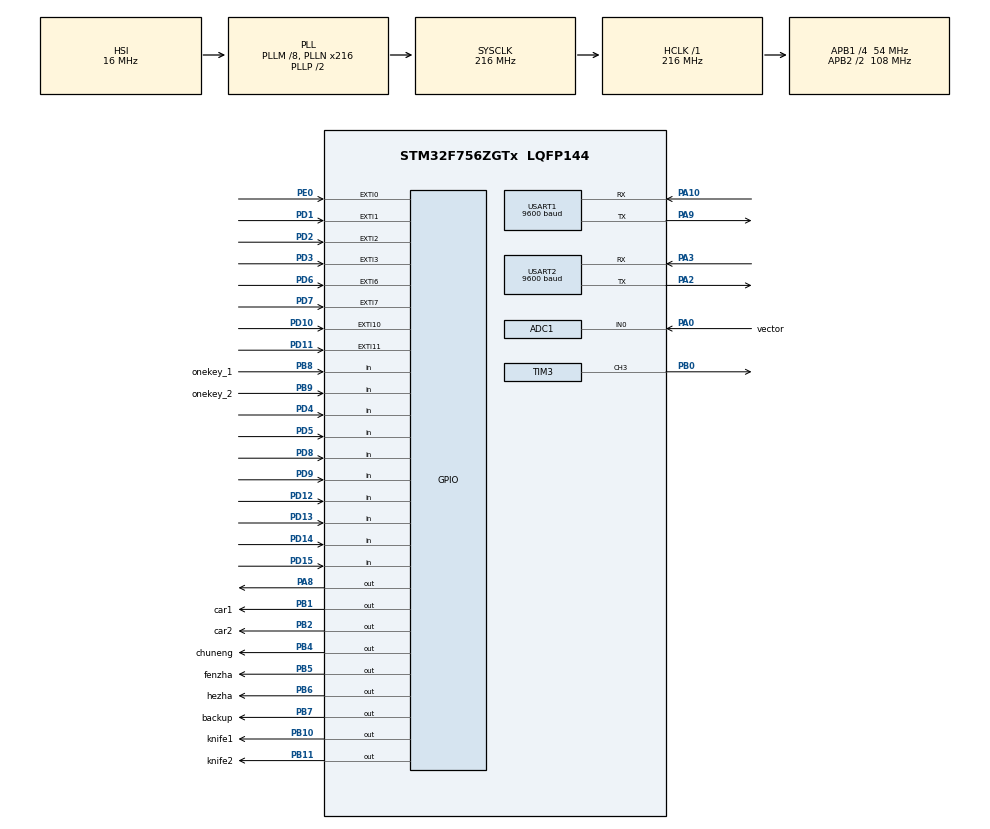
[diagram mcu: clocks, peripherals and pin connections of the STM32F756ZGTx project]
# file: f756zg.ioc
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ADC1.Channel-2\#ChannelRegularConversion=ADC_CHANNEL_0
ADC1.ClockPrescaler=ADC_CLOCK_SYNC_PCLK_DIV8
ADC1.ContinuousConvMode=ENABLE
ADC1.DMAContinuousRequests=ENABLE
ADC1.InjNumberOfConversion=0
ADC1.NbrOfConversionFlag=1
ADC1.Rank-2\#ChannelRegularConversion=1
ADC1.SamplingTime-2\#ChannelRegularConversion=ADC_SAMPLETIME_480CYCLES
ADC1.ScanConvMode=ADC_SCAN_ENABLE
ADC1.master=1
Dma.ADC1.0.Direction=DMA_PERIPH_TO_MEMORY
Dma.ADC1.0.FIFOMode=DMA_FIFOMODE_DISABLE
Dma.ADC1.0.Instance=DMA2_Stream0
Dma.ADC1.0.MemDataAlignment=DMA_MDATAALIGN_WORD
Dma.ADC1.0.MemInc=DMA_MINC_ENABLE
Dma.ADC1.0.Mode=DMA_CIRCULAR
Dma.ADC1.0.PeriphDataAlignment=DMA_PDATAALIGN_WORD
Dma.ADC1.0.PeriphInc=DMA_PINC_DISABLE
Dma.ADC1.0.Priority=DMA_PRIORITY_LOW
Dma.Request0=ADC1
Mcu.Family=STM32F7
Mcu.Name=STM32F756ZGTx
Mcu.Package=LQFP144
NVIC.DMA2_Stream0_IRQn=true\:0\:0\:false\:false\:true\:false\:true
NVIC.EXTI0_IRQn=true\:2\:0\:true\:false\:true\:true\:true
NVIC.EXTI15_10_IRQn=true\:2\:0\:true\:false\:true\:true\:true
NVIC.EXTI1_IRQn=true\:2\:0\:true\:false\:true\:true\:true
NVIC.EXTI2_IRQn=true\:2\:0\:true\:false\:true\:true\:true
NVIC.EXTI3_IRQn=true\:2\:0\:true\:false\:true\:true\:true
NVIC.EXTI9_5_IRQn=true\:2\:0\:true\:false\:true\:true\:true
NVIC.PriorityGroup=NVIC_PRIORITYGROUP_4
NVIC.TIM3_IRQn=true\:1\:0\:true\:false\:true\:true\:true
NVIC.TIM6_DAC_IRQn=true\:5\:0\:true\:true\:true\:1\:true\:true
PA0/WKUP.GPIO_Label=vector
PA0/WKUP.Signal=SharedAnalog_PA0
PA10.Mode=Asynchronous
PA10.Signal=USART1_RX
PA13.Mode=Serial_Wire
PA13.Signal=SYS_JTMS-SWDIO
PA14.Mode=Serial_Wire
PA14.Signal=SYS_JTCK-SWCLK
PA2.Mode=Asynchronous
PA2.Signal=USART2_TX
PA3.Mode=Asynchronous
PA3.Signal=USART2_RX
PA8.Signal=GPIO_Output
PA9.Mode=Asynchronous
PA9.Signal=USART1_TX
PB0.Signal=S_TIM3_CH3
PB1.GPIO_Label=car1
PB1.Signal=GPIO_Output
PB10.GPIO_Label=knife1
PB10.Signal=GPIO_Output
PB11.GPIO_Label=knife2
PB11.Signal=GPIO_Output
PB2.GPIO_Label=car2
PB2.Signal=GPIO_Output
PB4.GPIO_Label=chuneng
PB4.GPIO_ModeDefaultOutputPP=GPIO_MODE_OUTPUT_PP
PB4.GPIO_PuPd=GPIO_NOPULL
PB4.GPIO_Speed=GPIO_SPEED_FREQ_LOW
PB4.PinState=GPIO_PIN_RESET
PB4.Signal=GPIO_Output
PB5.GPIO_Label=fenzha
PB5.Signal=GPIO_Output
PB6.GPIO_Label=hezha
PB6.Signal=GPIO_Output
PB7.GPIO_Label=backup
PB7.Signal=GPIO_Output
PB8.GPIO_Label=onekey_1
PB8.GPIO_PuPd=GPIO_PULLDOWN
PB8.Signal=GPIO_Input
PB9.GPIO_Label=onekey_2
PB9.GPIO_PuPd=GPIO_PULLDOWN
PB9.Signal=GPIO_Input
PD1.GPIO_ModeDefaultEXTI=GPIO_MODE_IT_RISING
PD1.GPIO_PuPd=GPIO_PULLUP
PD1.Signal=GPXTI1
PD10.GPIO_ModeDefaultEXTI=GPIO_MODE_IT_RISING
PD10.GPIO_PuPd=GPIO_PULLUP
PD10.Signal=GPXTI10
PD11.GPIO_ModeDefaultEXTI=GPIO_MODE_IT_RISING
PD11.GPIO_PuPd=GPIO_PULLUP
PD11.Signal=GPXTI11
PD12.GPIO_PuPd=GPIO_PULLDOWN
PD12.Signal=GPIO_Input
PD13.GPIO_PuPd=GPIO_PULLDOWN
PD13.Signal=GPIO_Input
PD14.GPIO_PuPd=GPIO_PULLDOWN
PD14.Signal=GPIO_Input
PD15.GPIO_PuPd=GPIO_PULLDOWN
PD15.Signal=GPIO_Input
PD2.GPIO_ModeDefaultEXTI=GPIO_MODE_IT_RISING
PD2.GPIO_PuPd=GPIO_PULLUP
PD2.Signal=GPXTI2
PD3.GPIO_ModeDefaultEXTI=GPIO_MODE_IT_RISING
PD3.GPIO_PuPd=GPIO_PULLUP
PD3.Signal=GPXTI3
PD4.GPIO_PuPd=GPIO_PULLDOWN
PD4.Signal=GPIO_Input
PD5.GPIO_PuPd=GPIO_PULLDOWN
PD5.Signal=GPIO_Input
PD6.GPIO_ModeDefaultEXTI=GPIO_MODE_IT_RISING
PD6.GPIO_PuPd=GPIO_PULLUP
PD6.Signal=GPXTI6
PD7.GPIO_ModeDefaultEXTI=GPIO_MODE_IT_RISING
PD7.GPIO_PuPd=GPIO_PULLUP
PD7.Signal=GPXTI7
PD8.GPIO_PuPd=GPIO_PULLDOWN
PD8.Signal=GPIO_Input
PD9.GPIO_PuPd=GPIO_PULLDOWN
PD9.Signal=GPIO_Input
PE0.GPIO_ModeDefaultEXTI=GPIO_MODE_IT_RISING
PE0.GPIO_PuPd=GPIO_PULLUP
PE0.Signal=GPXTI0
PH0/OSC_IN.Mode=HSE-External-Oscillator
PH0/OSC_IN.Signal=RCC_OSC_IN
PH1/OSC_OUT.Mode=HSE-External-Oscillator
PH1/OSC_OUT.Signal=RCC_OSC_OUT
ProjectManager.HeapSize=0x200
ProjectManager.StackSize=0x400
ProjectManager.TargetToolchain=STM32CubeIDE
RCC.AHBFreq_Value=216000000
RCC.APB1CLKDivider=RCC_HCLK_DIV4
RCC.APB1Freq_Value=54000000
RCC.APB1TimFreq_Value=108000000
RCC.APB2CLKDivider=RCC_HCLK_DIV2
RCC.APB2Freq_Value=108000000
RCC.APB2TimFreq_Value=216000000
RCC.CortexFreq_Value=216000000
RCC.HCLKFreq_Value=216000000
RCC.HSE_VALUE=25000000
RCC.HSI_VALUE=16000000
RCC.LSE_VALUE=32768
RCC.PLLM=8
RCC.PLLN=216
RCC.SYSCLKFreq_VALUE=216000000
RCC.SYSCLKSource=RCC_SYSCLKSOURCE_PLLCLK
RCC.USBFreq_Value=216000000
RCC.VCOOutputFreq_Value=432000000
SH.S_TIM3_CH3.0=TIM3_CH3,PWM Generation3 CH3
SH.SharedAnalog_PA0.0=GPIO_Analog
SH.SharedAnalog_PA0.1=ADC1_IN0,IN0
TIM14.AutoReloadPreload=TIM_AUTORELOAD_PRELOAD_DISABLE
TIM14.Period=65535
TIM14.Prescaler=107
TIM3.Channel-PWM\ Generation3\ CH3=TIM_CHANNEL_3
TIM3.Period=1000
TIM3.Prescaler=215
TIM3.Pulse-PWM\ Generation3\ CH3=1000
TIM6.Period=10000-1
TIM6.Prescaler=10800-1
USART1.BaudRate=9600
USART1.VirtualMode-Asynchronous=VM_ASYNC
USART2.BaudRate=9600
USART2.VirtualMode-Asynchronous=VM_ASYNC
VP_TIM14_VS_ClockSourceINT.Mode=Enable_Timer
VP_TIM6_VS_ClockSourceINT.Mode=Enable_Timer
board=custom

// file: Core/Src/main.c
/* USER CODE BEGIN Header */
/**
  ******************************************************************************
  * @file           : main.c
  * @brief          : Main program body
  ******************************************************************************
  * @attention
  *
  * <h2><center>&copy; Copyright (c) 2021 STMicroelectronics.
  * All rights reserved.</center></h2>
  *
  * This software component is licensed by ST under BSD 3-Clause license,
  * the "License"; You may not use this file except in compliance with the
  * License. You may obtain a copy of the License at:
  *                        opensource.org/licenses/BSD-3-Clause
  *
  ******************************************************************************
  */
/* USER CODE END Header */
#include "main.h"
#include "adc.h"
#include "dma.h"
#include "tim.h"
#include "usart.h"
#include "gpio.h"

/* USER CODE BEGIN Includes */
#include "stdio.h"
#include "string.h"
#include "stdlib.h"

/* USER CODE END Includes */

/* USER CODE BEGIN PTD */
uint16_t bufferx;
uint8_t i;
uint8_t cnt;
uint32_t ad1, ad2;
uint32_t ADC_Value[1];

uint32_t ADCsum_Value[8192];
uint32_t pbx[12];
uint32_t pex[1];
uint32_t pdx[16];
uint16_t statesum;

uint8_t aTxBuffer[1] = "134252\r\n";
uint8_t aRxBuffer1[1]; // 用来接收串口1发�?�的数据
uint8_t aRxBuffer2[1]; // 用来接收串口2发�?�的数据
uint16_t aRxBuffer2translate[1];
/* USER CODE END PTD */

/* USER CODE BEGIN PV */

__weak void HAL_Delay_us(uint32_t Delay_us)
{
  uint16_t wait = Delay_us;

  if (wait < UINT16_MAX) //设定定时器计数器阈�?�，也可注释�??????????????????????????????????
    wait++;

  __HAL_TIM_SET_COUNTER(&htim14, 0); //将CNT值设置为0

  HAL_TIM_Base_Start(&htim14); //启动定时�??????????????????????????????????

  while (__HAL_TIM_GET_COUNTER(&htim14) < wait) //查询计数器的计数值判�??????????????????????????????????
  {
  }

  HAL_TIM_Base_Stop(&htim14); //频繁�??????????????????????????????????启时，可以注释掉这句
}

__weak void Delay_ms(uint32_t Delay_ms)
{
  while (Delay_ms--)
  {
    HAL_Delay_us(1000);
  }
}
//void set_pwmPB1(uint16_t sth){
//	  htim3.Instance->CCR4 = sth;
//}

/* USER CODE END PV */

void SystemClock_Config(void);
static void MX_NVIC_Init(void);
/* USER CODE BEGIN PFP */
#include "stdio.h"
#include "string.h"
#include "stdlib.h"
#ifdef __GNUC__
#define PUTCHAR_PROTOTYPE int __io_putchar(int ch)
#else
#define PUTCHAR_PROTOTYPE int fputc(int ch, FILE *f)
#endif
PUTCHAR_PROTOTYPE
{
  HAL_UART_Transmit(&huart2, (uint8_t *)&ch, 1, 0xFFFF);
  return ch;
}

/* USER CODE END PFP */

int main(void)
{

  /* MCU Configuration--------------------------------------------------------*/

  /* Reset of all peripherals, Initializes the Flash interface and the Systick. */
  HAL_Init();

  /* Configure the system clock */
  SystemClock_Config();

  /* Initialize all configured peripherals */
  MX_GPIO_Init();
  MX_USART1_UART_Init();
  MX_DMA_Init();
  MX_ADC1_Init();
  MX_TIM3_Init();
  MX_TIM14_Init();
  MX_TIM6_Init();
  MX_USART2_UART_Init();

  /* Initialize interrupts */
  MX_NVIC_Init();
  /* USER CODE BEGIN 2 */

  //  HAL_ADC_Start(&hadc1);//启动ADC装换
  //  HAL_ADC_PollForConversion(&hadc1, 10);
  //PB0    调�??
  HAL_TIM_PWM_Start(&htim3, TIM_CHANNEL_3); //A03  底盘车电�???????????????????????????????????????????  �???????????????????????????????????????????个触�???????????????????????????????????????????
  __HAL_TIM_SET_COMPARE(&htim3, TIM_CHANNEL_3, 0);
  // HAL_TIM_PWM_Start(&htim3, TIM_CHANNEL_4); //A04 底盘车电�??????????????????????????????????????????? 另一个触�???????????????????????????????????????????
  // __HAL_TIM_SET_COMPARE(&htim3, TIM_CHANNEL_4, 0);

  // // // HAL_TIM_PWM_Stop();
  // HAL_TIM_PWM_Start(&htim4, TIM_CHANNEL_3); //A05 接地�???????????????????????????????????????????电机 �???????????????????????????????????????????个触�???????????????????????????????????????????
  // __HAL_TIM_SET_COMPARE(&htim4, TIM_CHANNEL_3, 0);
  // HAL_TIM_PWM_Start(&htim4, TIM_CHANNEL_4); //A06 接地�???????????????????????????????????????????电机 另一个触�???????????????????????????????????????????
  // __HAL_TIM_SET_COMPARE(&htim4, TIM_CHANNEL_4, 0);
  //
  HAL_GPIO_WritePin(GPIOB, GPIO_PIN_4, GPIO_PIN_SET); //A07 储能电机
  HAL_GPIO_WritePin(GPIOB, GPIO_PIN_5, GPIO_PIN_SET); //A09 分闸线圈
  HAL_GPIO_WritePin(GPIOB, GPIO_PIN_6, GPIO_PIN_SET); //A10 合闸线圈
  HAL_GPIO_WritePin(GPIOB, GPIO_PIN_7, GPIO_PIN_SET); //A11 继电器合�???????????????????????????????????????????

  // PB8 PB9 Pullup 平时高电�?????????????????????? �??????????????????????测低电平  Pulldown 平时低电�?????????????????????? �??????????????????????测高电平
  HAL_GPIO_WritePin(GPIOB, GPIO_PIN_1, GPIO_PIN_SET);    //
  HAL_GPIO_WritePin(GPIOB, GPIO_PIN_2, GPIO_PIN_RESET);  //
  HAL_GPIO_WritePin(GPIOB, GPIO_PIN_10, GPIO_PIN_SET);   //
  HAL_GPIO_WritePin(GPIOB, GPIO_PIN_11, GPIO_PIN_RESET); //

  HAL_GPIO_WritePin(GPIOD, GPIO_PIN_1, GPIO_PIN_SET);   //
  HAL_GPIO_WritePin(GPIOD, GPIO_PIN_2, GPIO_PIN_SET);   //
  HAL_GPIO_WritePin(GPIOD, GPIO_PIN_0, GPIO_PIN_SET); //

  //
  //  HAL_GPIO_WritePin(GPIOB, GPIO_PIN_4, GPIO_PIN_RESET); //A07 PB4 储能电机
  //  HAL_GPIO_WritePin(GPIOB, GPIO_PIN_5, GPIO_PIN_RESET); //A09 PB5 分闸线圈
  //  HAL_GPIO_WritePin(GPIOB, GPIO_PIN_6, GPIO_PIN_RESET); //A10 PB6 合闸线圈
  //  HAL_GPIO_WritePin(GPIOB, GPIO_PIN_7, GPIO_PIN_RESET); //A11 PB7 继电器合�???????????????????????????????????????????.

  //  HAL_GPIO_WritePin(GPIOB, GPIO_PIN_8, GPIO_PIN_SET); // PB8�??????????????????????件顺�??????????????????????1
  //  HAL_GPIO_WritePin(GPIOB, GPIO_PIN_9, GPIO_PIN_SET); // PB9�??????????????????????件顺�??????????????????????2
  //   HAL_GPIO_WritePin(GPIOB, GPIO_PIN_3, GPIO_PIN_SET); //
  //
  //  HAL_UART_Receive_IT(&huart1, aRxBuffer1, 1); // Enable the USART1 Interrupt
  //  HAL_UART_Receive_IT(&huart2, aRxBuffer2, 1); // Enable the USART2 Interrupt
  //  HAL_UART_Transmit(&huart1, aTxBuffer, sizeof(aTxBuffer), 100);
  //  HAL_UART_Transmit(&huart2, aTxBuffer, sizeof(aTxBuffer), 100);
  // HAL_TIM_Base_Start_IT(&htim6); // 启动定时�??????????????????????????3

  /* USER CODE END 2 */

  /* Infinite loop */
  /* USER CODE BEGIN WHILE */
  while (1)
  {
//	  HAL_GPIO_WritePin(GPIOB, GPIO_PIN_6, GPIO_PIN_RESET);
    //	  HAL_GPIO_WritePin(GPIOB, GPIO_PIN_4, GPIO_PIN_SET);
    //
    //     	  Delay_ms(1000);
    //     	 HAL_GPIO_WritePin(GPIOB, GPIO_PIN_4, GPIO_PIN_RESET);
    //     	 Delay_ms(1000);
    //     statesum = statesum+1;
    //     printf("%d\n",statesum);
    // HAL_GPIO_WritePin(GPIOD, GPIO_PIN_0, GPIO_PIN_RESET);   //
    pbx[0] = HAL_GPIO_ReadPin(GPIOB, GPIO_PIN_0);   //pwm speed
    pbx[1] = HAL_GPIO_ReadPin(GPIOB, GPIO_PIN_1);   //PB1 car1
    pbx[2] = HAL_GPIO_ReadPin(GPIOB, GPIO_PIN_2);   //PB2 car2
    pbx[3] = HAL_GPIO_ReadPin(GPIOB, GPIO_PIN_3);   //A14合闸按钮                                         重要5    [按钮  外部中断]
    pbx[4] = HAL_GPIO_ReadPin(GPIOB, GPIO_PIN_4);   //A23底盘车试验位�???????????????????????????????????????????                 {状�?�}
    pbx[5] = HAL_GPIO_ReadPin(GPIOB, GPIO_PIN_5);   //A24底盘车工作位�???????????????????????????????????????????                 {状�?�}
    pbx[6] = HAL_GPIO_ReadPin(GPIOB, GPIO_PIN_6);   //A25底盘车遥进按钮手�???????????????????????????????????????????                                重要6    [按钮  外部中断]
    pbx[7] = HAL_GPIO_ReadPin(GPIOB, GPIO_PIN_7);   //A26底盘车遥出按钮手�???????????????????????????????????????????                                重要7    [按钮  外部中断]
    pbx[8] = HAL_GPIO_ReadPin(GPIOB, GPIO_PIN_8);   //A08 储能电机辅助按钮 要和 A27弹簧未储能按钮配�???????????????????????????????????????????       重要4   [按钮  外部中断]
    pbx[9] = HAL_GPIO_ReadPin(GPIOB, GPIO_PIN_9);   //A12 手动分闸按钮  A21 遥控分闸出口                   重要1    [按钮  外部中断]
    pbx[10] = HAL_GPIO_ReadPin(GPIOB, GPIO_PIN_10); // PB11 knife1
    pbx[11] = HAL_GPIO_ReadPin(GPIOB, GPIO_PIN_11); // PB12 knife2

    pdx[0] = HAL_GPIO_ReadPin(GPIOD, GPIO_PIN_0);   //A08 储能电机辅助按钮 要和 A27弹簧未储能按钮配�???????????????????????????????????????????       重要4   [按钮  外部中断]
    pdx[1] = HAL_GPIO_ReadPin(GPIOD, GPIO_PIN_1);   //A12 手动分闸按钮  A21 遥控分闸出口                   重要1    [按钮  外部中断]
    pdx[2] = HAL_GPIO_ReadPin(GPIOD, GPIO_PIN_2);   //A13 保护分闸按钮                                    重要2    [按钮  外部中断]
    pdx[3] = HAL_GPIO_ReadPin(GPIOD, GPIO_PIN_3);   //A14合闸按钮                                         重要5    [按钮  外部中断]
    pdx[4] = HAL_GPIO_ReadPin(GPIOD, GPIO_PIN_4);   //A23底盘车试验位�???????????????????????????????????????????                 {状�?�}
    pdx[5] = HAL_GPIO_ReadPin(GPIOD, GPIO_PIN_5);   //A24底盘车工作位�???????????????????????????????????????????                 {状�?�}
    pdx[6] = HAL_GPIO_ReadPin(GPIOD, GPIO_PIN_6);   //A25底盘车遥进按钮手�???????????????????????????????????????????                                重要6    [按钮  外部中断]
    pdx[7] = HAL_GPIO_ReadPin(GPIOD, GPIO_PIN_7);   //A26底盘车遥出按钮手�???????????????????????????????????????????                                重要7    [按钮  外部中断]
    pdx[8] = HAL_GPIO_ReadPin(GPIOD, GPIO_PIN_8);   //A27弹簧未储�???????????????????????????????????????????                     {状�?�}
    pdx[9] = HAL_GPIO_ReadPin(GPIOD, GPIO_PIN_9);   //A29遥控允许                       {状�?�}
    pdx[10] = HAL_GPIO_ReadPin(GPIOD, GPIO_PIN_10); //A30接地�???????????????????????????????????????????合闸输入按钮                               重要8    [按钮  外部中断]
    pdx[11] = HAL_GPIO_ReadPin(GPIOD, GPIO_PIN_11); //A31接地�???????????????????????????????????????????分闸输入按钮                               重要3    [按钮  外部中断]
    pdx[12] = HAL_GPIO_ReadPin(GPIOD, GPIO_PIN_12); //A32接地�???????????????????????????????????????????机构合闸位置（信号快)      {状�?�}
    pdx[13] = HAL_GPIO_ReadPin(GPIOD, GPIO_PIN_13); //A33接地�???????????????????????????????????????????机构分闸位置（信号快)      {状�?�}
    pdx[14] = HAL_GPIO_ReadPin(GPIOD, GPIO_PIN_14); //A34接地�???????????????????????????????????????????合闸位置   要和A32 配合    {状�?�}
    pdx[15] = HAL_GPIO_ReadPin(GPIOD, GPIO_PIN_15); //A35接地�???????????????????????????????????????????分闸位置                  {状�?�}

    HAL_Delay(200);
    //�?????????????????????键断�?????????????????????
    //    if ((pdx[8] == 1) && (pbx[9] == 0))
    //    {
    //    }
    //
    //    //�?????????????????????键�?�电
    //    if ((pdx[8] == 0) && (pbx[9] == 1))
    //    {
    //    }

    //statesum  = pdx[0] | pdx[1] | pdx[2] | pdx[3] | pdx[4] | pdx[5]| pdx[6]| pdx[7]| pdx[8] | pdx[9] |pdx[10] | pdx[11] | pdx[12] | pdx[13] | pdx[14] | pdx[15];
    //statesum  = pdx[4] | pdx[5] | pdx[8] | pdx[9] | pdx[12] | pdx[13] | pdx[14] | pdx[15];

    // 断路器合�???????????????????????????
    // printf("start\n");
    //	  HAL_ADC_Start(&hadc1);//启动ADC装换
    //	  HAL_ADC_PollForConversion(&hadc1, 10);//等待转换完成，第二个参数表示超时时间
    //	  if(HAL_IS_BIT_SET(HAL_ADC_GetState(&hadc1), HAL_ADC_STATE_REG_EOC)){
    //	  bufferx = HAL_ADC_GetValue(&hadc1);//读取ADC转换数据，数据为12�???????????????????????????????????????????
    //	  printf("[\tmain]info:v=%.1fmv\r\n",AD_Value );//打印日志
    //	  }

    //  ad1 =0;

    //
    //
    //	  HAL_ADC_Start_DMA(&hadc1, (uint32_t*)&ADC_Value,100);
    //	//   HAL_Delay(1);
    ////	  for(i = 0,ad1 =0; i < 1;){
    ////	  ad1 += ADC_Value[i++];
    ////	  }
    //	 // ad1 =  ADC_Value[0];
    //	//  ad1 = ad1/10;
    // 	  printf("%ld\n",  ADC_Value[0] );

    /* USER CODE END WHILE */

  }
}

void SystemClock_Config(void)
{
  RCC_OscInitTypeDef RCC_OscInitStruct = {0};
  RCC_ClkInitTypeDef RCC_ClkInitStruct = {0};
  RCC_PeriphCLKInitTypeDef PeriphClkInitStruct = {0};

  /** Configure the main internal regulator output voltage
  */
  __HAL_RCC_PWR_CLK_ENABLE();
  __HAL_PWR_VOLTAGESCALING_CONFIG(PWR_REGULATOR_VOLTAGE_SCALE1);
  /** Initializes the RCC Oscillators according to the specified parameters
  * in the RCC_OscInitTypeDef structure.
  */
  RCC_OscInitStruct.OscillatorType = RCC_OSCILLATORTYPE_HSI;
  RCC_OscInitStruct.HSIState = RCC_HSI_ON;
  RCC_OscInitStruct.HSICalibrationValue = RCC_HSICALIBRATION_DEFAULT;
  RCC_OscInitStruct.PLL.PLLState = RCC_PLL_ON;
  RCC_OscInitStruct.PLL.PLLSource = RCC_PLLSOURCE_HSI;
  RCC_OscInitStruct.PLL.PLLM = 8;
  RCC_OscInitStruct.PLL.PLLN = 216;
  RCC_OscInitStruct.PLL.PLLP = RCC_PLLP_DIV2;
  RCC_OscInitStruct.PLL.PLLQ = 2;
  if (HAL_RCC_OscConfig(&RCC_OscInitStruct) != HAL_OK)
  {
    Error_Handler();
  }
  /** Activate the Over-Drive mode
  */
  if (HAL_PWREx_EnableOverDrive() != HAL_OK)
  {
    Error_Handler();
  }
  /** Initializes the CPU, AHB and APB buses clocks
  */
  RCC_ClkInitStruct.ClockType = RCC_CLOCKTYPE_HCLK|RCC_CLOCKTYPE_SYSCLK
                              |RCC_CLOCKTYPE_PCLK1|RCC_CLOCKTYPE_PCLK2;
  RCC_ClkInitStruct.SYSCLKSource = RCC_SYSCLKSOURCE_PLLCLK;
  RCC_ClkInitStruct.AHBCLKDivider = RCC_SYSCLK_DIV1;
  RCC_ClkInitStruct.APB1CLKDivider = RCC_HCLK_DIV4;
  RCC_ClkInitStruct.APB2CLKDivider = RCC_HCLK_DIV2;

  if (HAL_RCC_ClockConfig(&RCC_ClkInitStruct, FLASH_LATENCY_7) != HAL_OK)
  {
    Error_Handler();
  }
  PeriphClkInitStruct.PeriphClockSelection = RCC_PERIPHCLK_USART1|RCC_PERIPHCLK_USART2;
  PeriphClkInitStruct.Usart1ClockSelection = RCC_USART1CLKSOURCE_PCLK2;
  PeriphClkInitStruct.Usart2ClockSelection = RCC_USART2CLKSOURCE_PCLK1;
  if (HAL_RCCEx_PeriphCLKConfig(&PeriphClkInitStruct) != HAL_OK)
  {
    Error_Handler();
  }
}

/**
  * @brief NVIC Configuration.
  * @retval None
  */
static void MX_NVIC_Init(void)
{
  /* TIM6_DAC_IRQn interrupt configuration */
  HAL_NVIC_SetPriority(TIM6_DAC_IRQn, 5, 0);
  HAL_NVIC_EnableIRQ(TIM6_DAC_IRQn);
}

/* USER CODE BEGIN 4 */

//unsigned short ModBusCRC(unsigned char *pData, unsigned int siLen)
//{
//  if (NULL == pData || siLen <= 0)
//  {
//    return 0;
//  }
//  unsigned short u16CRC = 0xFFFF;
//  int i = 0;
//  int j = 0;
//  for (i = 0; i < siLen; i++)
//  {
//    u16CRC ^= (unsigned short)(pData[i]);
//    for (j = 0; j <= 7; j++)
//    {
//      if (u16CRC & 0x0001)
//      {
//        u16CRC = (u16CRC >> 1) ^ 0xA001;
//      }
//      else
//      {
//        u16CRC = u16CRC >> 1;
//      }
//    }
//  }
//
//  unsigned short siRet = 0;
//  siRet = (u16CRC & 0x00FF) << 8;
//  siRet |= u16CRC >> 8;
//  return siRet;
//}
//
//unsigned int CRC16(unsigned char *arr_buff, unsigned int len)
//{
//  unsigned int crc = 0xFFFF;
//  unsigned char i, j, Data;
//  for (j = 0; j < len; j++)
//  {
//    crc = crc ^ *arr_buff++;
//    for (i = 0; i < 8; i++)
//    {
//
//      if ((crc & 0x0001) > 0)
//
//      {
//
//        crc = crc >> 1;
//
//        crc = crc ^ 0xa001;
//      }
//      else
//
//        crc = crc >> 1;
//    }
//  }
//  return (crc);
//}
//
//void HAL_UART_RxCpltCallback(UART_HandleTypeDef *huart)
//{
//  //TX-White RX-Green
//  // UART1 PA9(TX) PA10(RX)
//  // UART1 PA2(TX) PA3(RX)
//  if (huart->Instance == USART1) // 判断是由哪个串口触发的中�??????????????????????????
//  {
//    HAL_UART_Transmit(&huart1, aRxBuffer1, 1, 100); // 接收到数据马上使用串�??????????????????????????1发�?�出�??????????????????????????
//    HAL_UART_Receive_IT(&huart1, aRxBuffer1, 1);    // 重新使能串口1接收中断
//  }
//  if (huart->Instance == USART2)
//  {
//    uint8_t aRxBuffer2size = sizeof(aRxBuffer2);
//
//    //		aRxBuffer2translate  = MB_CRC16(aRxBuffer2, aRxBuffer2size );
//    //
//    //	    HAL_UART_Transmit(&huart2,(uint8_t *)aRxBuffer2translate>>8,1,100);	// 接收到数据马上使用串�??????????????????????????1发�?�出�??????????????????????????
//
//    //		HAL_UART_Transmit(&huart2,aRxBuffer2,1,100);	// 接收到数据马上使用串�??????????????????????????1发�?�出�??????????????????????????
//    HAL_UART_Receive_IT(&huart2, aRxBuffer2, 1); // 重新使能串口2接收中断
//  }
//}
//void HAL_TIM_PeriodElapsedCallback(TIM_HandleTypeDef *htim)
//{
//  //	if(htim->Instance == TIM6)		// 判断是由哪个定时器触发的中断
//  //	{
//  //		//HAL_GPIO_TogglePin(GPIOA,GPIO_PIN_8);
//  //		printf("TIM6 interrupt\n");
//  //	}
//}

//PD0 A08 储能电机辅助按钮 要和 A27弹簧未储能按钮配�???????????????????????????????????????????       重要4   [按钮  外部中断]
//PD1 A12 手动分闸按钮  A21 遥控分闸出口                   重要1    [按钮  外部中断]
//PD2 A13 保护分闸按钮                                    重要2    [按钮  外部中断]
//PD3 A14 合闸按钮                                         重要5    [按钮  外部中断]
//PD4 A23 底盘车试验位�???????????????????????????????????????????                 {状�?�}
//PD5 A24 底盘车工作位�???????????????????????????????????????????                 {状�?�}
//PD6 A26 底盘车遥出按钮手�???????????????????????????????????????????                                重要7    [按钮  外部中断]
//PD7 A25 底盘车遥进按钮手�???????????????????????????????????????????                                重要6    [按钮  外部中断]
//PD8 A27 弹簧未储�???????????????????????????????????????????                     {状�?�}
//PD9 A29 遥控允许                       {状�?�}
//PD10 A30 接地�???????????????????????????????????????????合闸输入按钮                               重要8    [按钮  外部中断]
//PD11 A31 接地�???????????????????????????????????????????分闸输入按钮                               重要3    [按钮  外部中断]
//PD12 A32 接地�???????????????????????????????????????????机构合闸位置（信号快)      {状�?�}
//PD13 A33 接地�???????????????????????????????????????????机构分闸位置（信号快)      {状�?�}
//PD14 A34 接地�???????????????????????????????????????????合闸位置   要和A32 配合    {状�?�}
//PD15 A35 接地�???????????????????????????????????????????分闸位置                  {状�?�}
// HAL_TIM_PWM_Start(&htim3, TIM_CHANNEL_3); //PB0    A03  底盘车电�???????????????????????????????????????????  �???????????????????????????????????????????个触�???????????????????????????????????????????
// __HAL_TIM_SET_COMPARE(&htim3, TIM_CHANNEL_3, 1000);
// HAL_TIM_PWM_Start(&htim3, TIM_CHANNEL_4); //PB1    A04 底盘车电�??????????????????????????????????????????? 另一个触�???????????????????????????????????????????
// __HAL_TIM_SET_COMPARE(&htim3, TIM_CHANNEL_4, 0);

// // // HAL_TIM_PWM_Stop();
// HAL_TIM_PWM_Start(&htim4, TIM_CHANNEL_3); //PB8    A05 接地�???????????????????????????????????????????电机 �???????????????????????????????????????????个触�???????????????????????????????????????????
// __HAL_TIM_SET_COMPARE(&htim4, TIM_CHANNEL_3, 500);
// HAL_TIM_PWM_Start(&htim4, TIM_CHANNEL_4); //PB9    A06 接地�???????????????????????????????????????????电机 另一个触�???????????????????????????????????????????
// __HAL_TIM_SET_COMPARE(&htim4, TIM_CHANNEL_4, 0);

// HAL_GPIO_WritePin(GPIOB, GPIO_PIN_4, GPIO_PIN_RESET); //A07 储能电机
// HAL_GPIO_WritePin(GPIOB, GPIO_PIN_5, GPIO_PIN_RESET); //A09 分闸线圈
// HAL_GPIO_WritePin(GPIOB, GPIO_PIN_6, GPIO_PIN_RESET); //A10 合闸线圈
// HAL_GPIO_WritePin(GPIOB, GPIO_PIN_7, GPIO_PIN_RESET); //A11 继电器合�???????????????????????????????????????????

void HAL_GPIO_EXTI_Callback(uint16_t GPIO_Pin)
{
  //  HAL_GPIO_WritePin(GPIOB, GPIO_PIN_7, GPIO_PIN_SET);
  //  pex[0] = HAL_GPIO_ReadPin(GPIOE, GPIO_PIN_0);
  // HAL_Delay(300);
  ///////////////////*************************************************/////////////////////////////////////////
  ///////////////////**************************  0  *******************/////////////////////////////////////////
  ///////////////////*************************************************/////////////////////////////////////////

  //PD0 A08 储能电机辅助按钮 要和 A27弹簧未储能按钮配�?????????????????????????????????????????????       重要4   [按钮  外部中断]
  //已捕获PD0 弹簧未储�?????????????????????????????????????????????, 则弹簧储�?????????????????????????????????????????????  �?????????????????????????????????????????????�????????????????????????????????????????????? 捕捉弹簧现在未储能状态PD8 �????????????????????????????????????????????? 远控允许PD9
  //0 弹簧储能 tanhuangchuneng
  if (GPIO_Pin == GPIO_PIN_0)
  {
    HAL_Delay(10);
    cnt = 0 ;
    pdx[0] = HAL_GPIO_ReadPin(GPIOB, GPIO_PIN_0);
    pbx[4] = HAL_GPIO_ReadPin(GPIOB, GPIO_PIN_4);
    pdx[8] = HAL_GPIO_ReadPin(GPIOD, GPIO_PIN_8);
    if (pdx[8])
    {
    	HAL_Delay(500);
    }

    if (pdx[8])
    {
      HAL_GPIO_WritePin(GPIOB, GPIO_PIN_4, GPIO_PIN_RESET);
      HAL_Delay(6000);
      if ((pdx[8]==1) && (cnt<=6) ){
    	  HAL_GPIO_WritePin(GPIOB, GPIO_PIN_4, GPIO_PIN_RESET);
    	  HAL_Delay(2000);
    	  cnt++;
      }
      else {
    	  HAL_GPIO_WritePin(GPIOB, GPIO_PIN_4, GPIO_PIN_SET);
    	       HAL_Delay(2000);
      }
      pdx[8] = HAL_GPIO_ReadPin(GPIOD, GPIO_PIN_8);
      if ((pdx[8]==1) && (cnt<=6) ){
         	  HAL_GPIO_WritePin(GPIOB, GPIO_PIN_4, GPIO_PIN_RESET);
         	  HAL_Delay(2000);
         	  cnt++;
           }
           else {
         	  HAL_GPIO_WritePin(GPIOB, GPIO_PIN_4, GPIO_PIN_SET);
         	       HAL_Delay(2000);
           }
      pdx[8] = HAL_GPIO_ReadPin(GPIOD, GPIO_PIN_8);
      if ((pdx[8]==1) && (cnt<=6) ){
         	  HAL_GPIO_WritePin(GPIOB, GPIO_PIN_4, GPIO_PIN_RESET);
         	  HAL_Delay(2000);
         	  cnt++;
           }
           else {
         	  HAL_GPIO_WritePin(GPIOB, GPIO_PIN_4, GPIO_PIN_SET);
         	       HAL_Delay(2000);
           }
      pdx[8] = HAL_GPIO_ReadPin(GPIOD, GPIO_PIN_8);
      if ((pdx[8]==1) && (cnt<=6) ){
          	  HAL_GPIO_WritePin(GPIOB, GPIO_PIN_4, GPIO_PIN_RESET);
          	  HAL_Delay(2000);
          	  cnt++;
            }
            else {
          	  HAL_GPIO_WritePin(GPIOB, GPIO_PIN_4, GPIO_PIN_SET);
          	       HAL_Delay(2000);
            }
      pdx[8] = HAL_GPIO_ReadPin(GPIOD, GPIO_PIN_8);
            if ((pdx[8]==1) && (cnt<=6) ){
               	  HAL_GPIO_WritePin(GPIOB, GPIO_PIN_4, GPIO_PIN_RESET);
               	  HAL_Delay(2000);
               	  cnt++;
                 }
                 else {
               	  HAL_GPIO_WritePin(GPIOB, GPIO_PIN_4, GPIO_PIN_SET);
               	       HAL_Delay(2000);
                 }
            pdx[8] = HAL_GPIO_ReadPin(GPIOD, GPIO_PIN_8);
            if ((pdx[8]==1) && (cnt<=6) ){
               	  HAL_GPIO_WritePin(GPIOB, GPIO_PIN_4, GPIO_PIN_RESET);
               	  HAL_Delay(2000);
               	  cnt++;
                 }
                 else {
               	  HAL_GPIO_WritePin(GPIOB, GPIO_PIN_4, GPIO_PIN_SET);
               	       HAL_Delay(2000);
                 }

      HAL_GPIO_WritePin(GPIOB, GPIO_PIN_4, GPIO_PIN_SET);
      HAL_Delay(2000);
      HAL_GPIO_WritePin(GPIOE, GPIO_PIN_0, GPIO_PIN_SET);
    }
  }
  ///////////////////*************************************************/////////////////////////////////////////
  ///////////////////**************************  1  *******************/////////////////////////////////////////
  ///////////////////*************************************************/////////////////////////////////////////

  //PD1 A12 手动分闸按钮  A21 遥控分闸出口                   重要1    [按钮  外部中断]
  //已捕获PD1 手动分闸,直接分闸 �????????????????????????????????????????????? !远控允许PD9必须�??????????????????????                                                          ???????????????????????0 �????????????????????????????????????????????? 底盘车工作位置PD5
  //由于紧�?�分�????????????????????????????????????????????? 不�?�虑以下情况:  �????????????????????????????????????????????? PD13 接地�?????????????????????????????????????????????机构分闸位置（信号快)  �????????????????????????????????????????????? PD15 接地�?????????????????????????????????????????????分闸位置 �????????????????????????????????????????????? PD3 合闸按钮必须�?????????????????????????????????????????????0
  //1 手动分闸 shoudongfenzha
  if (GPIO_Pin == GPIO_PIN_1)
  {
    pdx[5] = !HAL_GPIO_ReadPin(GPIOD, GPIO_PIN_5);
    pdx[9] = !HAL_GPIO_ReadPin(GPIOD, GPIO_PIN_9);
    if (pdx[5] && (!pdx[9]))
    {
      HAL_GPIO_WritePin(GPIOB, GPIO_PIN_5, GPIO_PIN_RESET);
      HAL_Delay(1000);
      HAL_GPIO_WritePin(GPIOB, GPIO_PIN_5, GPIO_PIN_SET);
      HAL_Delay(5000);
      HAL_GPIO_WritePin(GPIOD, GPIO_PIN_1, GPIO_PIN_SET);
    }

    if (pdx[5] && pdx[9])
    {
      HAL_GPIO_WritePin(GPIOB, GPIO_PIN_5, GPIO_PIN_RESET);
      HAL_Delay(1000);
      HAL_GPIO_WritePin(GPIOB, GPIO_PIN_5, GPIO_PIN_SET);
      HAL_Delay(5000);
      HAL_GPIO_WritePin(GPIOD, GPIO_PIN_1, GPIO_PIN_SET);
    }

  }

  ///////////////////*************************************************/////////////////////////////////////////
  ///////////////////**************************  2  *******************/////////////////////////////////////////
  ///////////////////*************************************************/////////////////////////////////////////

  //PD2 A13 保护分闸按钮                                    重要2    [按钮  外部中断]
  //已捕获PD1 手动分闸,直接分闸 �????????????????????????????????????????????? 远控允许PD9 �????????????????????????????????????????????? 底盘车工作位置PD5
  //由于非紧急分�????????????????????????????????????????????? 考虑以下情况:  �????????????????????????????????????????????? PD13 接地�?????????????????????????????????????????????机构分闸位置（信号快)  �????????????????????????????????????????????? PD15 接地�?????????????????????????????????????????????分闸位置 �????????????????????????????????????????????? PD3 !合闸按钮必须�?????????????????????????????????????????????0
  //2 保护分闸 baohufenzha
  if (GPIO_Pin == GPIO_PIN_2)
  {
    pdx[5] = !HAL_GPIO_ReadPin(GPIOD, GPIO_PIN_5);
    pdx[9] = !HAL_GPIO_ReadPin(GPIOD, GPIO_PIN_9);
    if (pdx[5] && pdx[9])
    {
      HAL_GPIO_WritePin(GPIOB, GPIO_PIN_5, GPIO_PIN_RESET);
      HAL_Delay(1000);
      HAL_GPIO_WritePin(GPIOB, GPIO_PIN_5, GPIO_PIN_SET);
      HAL_Delay(5000);
      HAL_GPIO_WritePin(GPIOD, GPIO_PIN_2, GPIO_PIN_SET);
    }
    if (pdx[5] && (!pdx[9]))
    {
      HAL_GPIO_WritePin(GPIOB, GPIO_PIN_5, GPIO_PIN_RESET);
      HAL_Delay(1000);
      HAL_GPIO_WritePin(GPIOB, GPIO_PIN_5, GPIO_PIN_SET);
      HAL_Delay(5000);
      HAL_GPIO_WritePin(GPIOD, GPIO_PIN_2, GPIO_PIN_SET);
    }
  }

  ///////////////////*************************************************/////////////////////////////////////////
  ///////////////////**************************  3  *******************/////////////////////////////////////////
  ///////////////////*************************************************/////////////////////////////////////////

  //PD3 A14合闸按钮                                         重要5    [按钮  外部中断]
  //已捕获PD3 合闸,直接合闸 �????????????????????????????????????????????? 远控允许PD9 �????????????????????????????????????????????? 底盘车工作位置PD5 �????????????????????????????????????????????? 底盘车在试验位置PD4
  //由于非紧急合�????????????????????????????????????????????? 考虑以下情况:      �????????????????????????????????????????????? PD15 接地�?????????????????????????????????????????????分闸位置 �?????????????????????????????????????????????     �????????????????????????????????????????????? PD2 !保护分闸按钮必须�?????????????????????????????????????????????0 �????????????????????????????????????????????? PD8!弹簧未储能必�????????????????????????????????????????????? 0
  //3 手动合闸 shoudonghezha
  if (GPIO_Pin == GPIO_PIN_3)
  {
    pdx[4] = HAL_GPIO_ReadPin(GPIOD, GPIO_PIN_4);
    pdx[5] = HAL_GPIO_ReadPin(GPIOD, GPIO_PIN_5);
    pdx[9] =  HAL_GPIO_ReadPin(GPIOD, GPIO_PIN_9);
    pdx[15] = HAL_GPIO_ReadPin(GPIOD, GPIO_PIN_15);
    pdx[8] = HAL_GPIO_ReadPin(GPIOD, GPIO_PIN_8);
//    if ((pdx[5] || pdx[4])  && (!pdx[8]) && (!pdx[9]))
//    {
//      HAL_GPIO_WritePin(GPIOB, GPIO_PIN_6, GPIO_PIN_RESET); //A10 合闸线圈
//      HAL_Delay(1000);
//      HAL_GPIO_WritePin(GPIOB, GPIO_PIN_6, GPIO_PIN_SET); //A10 合闸线圈
//      HAL_Delay(5000);
//      HAL_GPIO_WritePin(GPIOD, GPIO_PIN_3, GPIO_PIN_SET);
//    }
//    if ((pdx[5] || pdx[4])  && (!pdx[8]) && pdx[9])
    if ( pdx[9])
    {
      HAL_GPIO_WritePin(GPIOB, GPIO_PIN_6, GPIO_PIN_RESET); //A10 合闸线圈
      HAL_Delay(1000);
      HAL_GPIO_WritePin(GPIOB, GPIO_PIN_6, GPIO_PIN_SET); //A10 合闸线圈
      HAL_GPIO_WritePin(GPIOD, GPIO_PIN_0, GPIO_PIN_SET); //
      HAL_Delay(5000);
      HAL_GPIO_WritePin(GPIOD, GPIO_PIN_3, GPIO_PIN_SET);
      HAL_GPIO_WritePin(GPIOD, GPIO_PIN_0, GPIO_PIN_SET); //
    }
  }
  ///////////////////*************************************************/////////////////////////////////////////
  ///////////////////**************************  6  *******************/////////////////////////////////////////
  ///////////////////*************************************************/////////////////////////////////////////

  //PD6 A26底盘车遥出按钮手�?????????????????????????????????????????????                                重要7    [按钮  外部中断]
  //PB7继电器�?�开关必须使�?????????????????????????????????????????????
  //已捕获PD6 底盘车手动推�?????????????????????????????????????????????  电机反转PB0 = 0 , PB1 = 1 �?????????????????????????????????????????????
  // !远控允许PD9必为0  �????????????????????????????????????????????? 底盘车工作位置PD5 �?????????????????????????????????????????????
  // PB7继电器�?�开关必须使能为1 �?????????????????????????????????????????????  !PB6 断路器必须不合闸 �?????????????????????????????????????????????
  //PD13 接地�?????????????????????????????????????????????机构分闸位置（信号快)  �?????????????????????????????????????????????
  //PD15 接地�?????????????????????????????????????????????分闸位置
  // 6 底盘车摇�????????????????????? dipancheyaochu
  if (GPIO_Pin == GPIO_PIN_6)
  {
    pdx[4] = !HAL_GPIO_ReadPin(GPIOD, GPIO_PIN_4);
    pdx[5] = !HAL_GPIO_ReadPin(GPIOD, GPIO_PIN_5);
    pdx[9] = !HAL_GPIO_ReadPin(GPIOD, GPIO_PIN_9);
    pdx[15] = !HAL_GPIO_ReadPin(GPIOD, GPIO_PIN_15);

    pbx[7] = HAL_GPIO_ReadPin(GPIOB, GPIO_PIN_7);
    pbx[6] = HAL_GPIO_ReadPin(GPIOB, GPIO_PIN_6);

    //工作位置摇出
    if (pdx[5] && pbx[7] && (!pbx[6]) && pdx[15] && (!pdx[9]))
    {
      HAL_TIM_PWM_Start(&htim3, TIM_CHANNEL_3); //PB0    A03  底盘车电�?????????????????????????????????????????????  �?????????????????????????????????????????????个触�?????????????????????????????????????????????
                                                // // HAL_TIM_PWM_Stop(&htim3, TIM_CHANNEL_3);
                                                // // HAL_TIM_PWM_Stop(&htim3, TIM_CHANNEL_4);
      // PB0   __HAL_TIM_SET_COMPARE(&htim3, TIM_CHANNEL_3, 0);

      __HAL_TIM_SET_COMPARE(&htim3, TIM_CHANNEL_3, 0);
      // HAL_GPIO_WritePin(GPIOB, GPIO_PIN_1, GPIO_PIN_RESET);
      // PB1   __HAL_TIM_SET_COMPARE(&htim3, TIM_CHANNEL_4, 0);
      HAL_Delay(1);
      //init motor
      HAL_GPIO_WritePin(GPIOB, GPIO_PIN_1, GPIO_PIN_SET);   //
      HAL_GPIO_WritePin(GPIOB, GPIO_PIN_2, GPIO_PIN_RESET); //

      __HAL_TIM_SET_COMPARE(&htim3, TIM_CHANNEL_3, 1000);
      HAL_Delay(1);
      HAL_GPIO_WritePin(GPIOB, GPIO_PIN_2, GPIO_PIN_SET);
      HAL_GPIO_WritePin(GPIOB, GPIO_PIN_1, GPIO_PIN_SET);

      HAL_GPIO_WritePin(GPIOB, GPIO_PIN_2, GPIO_PIN_RESET);
      HAL_Delay(5000);
      //init motor
      HAL_GPIO_WritePin(GPIOB, GPIO_PIN_1, GPIO_PIN_SET);   //
      HAL_GPIO_WritePin(GPIOB, GPIO_PIN_2, GPIO_PIN_RESET); //

      __HAL_TIM_SET_COMPARE(&htim3, TIM_CHANNEL_3, 500);
      HAL_GPIO_WritePin(GPIOB, GPIO_PIN_2, GPIO_PIN_RESET);
      HAL_GPIO_WritePin(GPIOB, GPIO_PIN_1, GPIO_PIN_RESET);
      HAL_Delay(100);
      //init motor
      HAL_GPIO_WritePin(GPIOB, GPIO_PIN_1, GPIO_PIN_SET);   //
      HAL_GPIO_WritePin(GPIOB, GPIO_PIN_2, GPIO_PIN_RESET); //
      //防抱�?????????????????????????????????????????????

      __HAL_TIM_SET_COMPARE(&htim3, TIM_CHANNEL_3, 0);
      HAL_TIM_PWM_Stop(&htim3, TIM_CHANNEL_3);

      //HAL_GPIO_WritePin(GPIOB, GPIO_PIN_1, GPIO_PIN_RESET);
      HAL_Delay(3000);
    }
    //非工作位�????????????????????? 非试验位置摇�?????????????????????
    if ((!pdx[5]) && (!pdx[4]) && pbx[7] && (!pbx[6]) && pdx[15] && (!pdx[9]))
    {
      HAL_TIM_PWM_Start(&htim3, TIM_CHANNEL_3); //PB0    A03  底盘车电�?????????????????????????????????????????????  �?????????????????????????????????????????????个触�?????????????????????????????????????????????
                                                // // HAL_TIM_PWM_Stop(&htim3, TIM_CHANNEL_3);
                                                // // HAL_TIM_PWM_Stop(&htim3, TIM_CHANNEL_4);
      // PB0   __HAL_TIM_SET_COMPARE(&htim3, TIM_CHANNEL_3, 0);

      __HAL_TIM_SET_COMPARE(&htim3, TIM_CHANNEL_3, 0);
      // HAL_GPIO_WritePin(GPIOB, GPIO_PIN_1, GPIO_PIN_RESET);
      // PB1   __HAL_TIM_SET_COMPARE(&htim3, TIM_CHANNEL_4, 0);
      HAL_Delay(1);
      //init motor
      HAL_GPIO_WritePin(GPIOB, GPIO_PIN_1, GPIO_PIN_SET);   //
      HAL_GPIO_WritePin(GPIOB, GPIO_PIN_2, GPIO_PIN_RESET); //

      __HAL_TIM_SET_COMPARE(&htim3, TIM_CHANNEL_3, 1000);
      HAL_Delay(1);
      HAL_GPIO_WritePin(GPIOB, GPIO_PIN_2, GPIO_PIN_SET);
      HAL_GPIO_WritePin(GPIOB, GPIO_PIN_1, GPIO_PIN_SET);

      HAL_GPIO_WritePin(GPIOB, GPIO_PIN_2, GPIO_PIN_RESET);
      HAL_Delay(5000);
      //init motor
      HAL_GPIO_WritePin(GPIOB, GPIO_PIN_1, GPIO_PIN_SET);   //
      HAL_GPIO_WritePin(GPIOB, GPIO_PIN_2, GPIO_PIN_RESET); //

      __HAL_TIM_SET_COMPARE(&htim3, TIM_CHANNEL_3, 500);
      HAL_GPIO_WritePin(GPIOB, GPIO_PIN_2, GPIO_PIN_RESET);
      HAL_GPIO_WritePin(GPIOB, GPIO_PIN_1, GPIO_PIN_RESET);
      HAL_Delay(100);
      //init motor
      HAL_GPIO_WritePin(GPIOB, GPIO_PIN_1, GPIO_PIN_SET);   //
      HAL_GPIO_WritePin(GPIOB, GPIO_PIN_2, GPIO_PIN_RESET); //
      //防抱�?????????????????????????????????????????????

      __HAL_TIM_SET_COMPARE(&htim3, TIM_CHANNEL_3, 0);
      HAL_TIM_PWM_Stop(&htim3, TIM_CHANNEL_3);

      //HAL_GPIO_WritePin(GPIOB, GPIO_PIN_1, GPIO_PIN_RESET);
      HAL_Delay(3000);
    }
    //工作位置摇出(远控允许)
    if (pdx[5] && pbx[7] && (!pbx[6]) && pdx[15] && pdx[9])
    {
      HAL_TIM_PWM_Start(&htim3, TIM_CHANNEL_3); //PB0    A03  底盘车电�?????????????????????????????????????????????  �?????????????????????????????????????????????个触�?????????????????????????????????????????????
                                                // // HAL_TIM_PWM_Stop(&htim3, TIM_CHANNEL_3);
                                                // // HAL_TIM_PWM_Stop(&htim3, TIM_CHANNEL_4);
      // PB0   __HAL_TIM_SET_COMPARE(&htim3, TIM_CHANNEL_3, 0);

      __HAL_TIM_SET_COMPARE(&htim3, TIM_CHANNEL_3, 0);
      // HAL_GPIO_WritePin(GPIOB, GPIO_PIN_1, GPIO_PIN_RESET);
      // PB1   __HAL_TIM_SET_COMPARE(&htim3, TIM_CHANNEL_4, 0);
      HAL_Delay(1);
      //init motor
      HAL_GPIO_WritePin(GPIOB, GPIO_PIN_1, GPIO_PIN_SET);   //
      HAL_GPIO_WritePin(GPIOB, GPIO_PIN_2, GPIO_PIN_RESET); //

      __HAL_TIM_SET_COMPARE(&htim3, TIM_CHANNEL_3, 1000);
      HAL_Delay(1);
      HAL_GPIO_WritePin(GPIOB, GPIO_PIN_2, GPIO_PIN_SET);
      HAL_GPIO_WritePin(GPIOB, GPIO_PIN_1, GPIO_PIN_SET);

      HAL_GPIO_WritePin(GPIOB, GPIO_PIN_2, GPIO_PIN_RESET);
      HAL_Delay(5000);
      //init motor
      HAL_GPIO_WritePin(GPIOB, GPIO_PIN_1, GPIO_PIN_SET);   //
      HAL_GPIO_WritePin(GPIOB, GPIO_PIN_2, GPIO_PIN_RESET); //

      __HAL_TIM_SET_COMPARE(&htim3, TIM_CHANNEL_3, 500);
      HAL_GPIO_WritePin(GPIOB, GPIO_PIN_2, GPIO_PIN_RESET);
      HAL_GPIO_WritePin(GPIOB, GPIO_PIN_1, GPIO_PIN_RESET);
      HAL_Delay(100);
      //init motor
      HAL_GPIO_WritePin(GPIOB, GPIO_PIN_1, GPIO_PIN_SET);   //
      HAL_GPIO_WritePin(GPIOB, GPIO_PIN_2, GPIO_PIN_RESET); //
      //防抱�?????????????????????????????????????????????

      __HAL_TIM_SET_COMPARE(&htim3, TIM_CHANNEL_3, 0);
      HAL_TIM_PWM_Stop(&htim3, TIM_CHANNEL_3);

      //HAL_GPIO_WritePin(GPIOB, GPIO_PIN_1, GPIO_PIN_RESET);
      HAL_Delay(3000);
    }
    //非工作位�????????????????????? 非试验位置摇�?????????????????????(远控允许)
    if ((!pdx[5]) && (!pdx[4]) && pbx[7] && (!pbx[6]) && pdx[15] && pdx[9])
    {
      HAL_TIM_PWM_Start(&htim3, TIM_CHANNEL_3); //PB0    A03  底盘车电�?????????????????????????????????????????????  �?????????????????????????????????????????????个触�?????????????????????????????????????????????
                                                // // HAL_TIM_PWM_Stop(&htim3, TIM_CHANNEL_3);
                                                // // HAL_TIM_PWM_Stop(&htim3, TIM_CHANNEL_4);
      // PB0   __HAL_TIM_SET_COMPARE(&htim3, TIM_CHANNEL_3, 0);

      __HAL_TIM_SET_COMPARE(&htim3, TIM_CHANNEL_3, 0);
      // HAL_GPIO_WritePin(GPIOB, GPIO_PIN_1, GPIO_PIN_RESET);
      // PB1   __HAL_TIM_SET_COMPARE(&htim3, TIM_CHANNEL_4, 0);
      HAL_Delay(1);
      //init motor
      HAL_GPIO_WritePin(GPIOB, GPIO_PIN_1, GPIO_PIN_SET);   //
      HAL_GPIO_WritePin(GPIOB, GPIO_PIN_2, GPIO_PIN_RESET); //

      __HAL_TIM_SET_COMPARE(&htim3, TIM_CHANNEL_3, 1000);
      HAL_Delay(1);
      HAL_GPIO_WritePin(GPIOB, GPIO_PIN_2, GPIO_PIN_SET);
      HAL_GPIO_WritePin(GPIOB, GPIO_PIN_1, GPIO_PIN_SET);

      HAL_GPIO_WritePin(GPIOB, GPIO_PIN_2, GPIO_PIN_RESET);
      HAL_Delay(5000);
      //init motor
      HAL_GPIO_WritePin(GPIOB, GPIO_PIN_1, GPIO_PIN_SET);   //
      HAL_GPIO_WritePin(GPIOB, GPIO_PIN_2, GPIO_PIN_RESET); //

      __HAL_TIM_SET_COMPARE(&htim3, TIM_CHANNEL_3, 500);
      HAL_GPIO_WritePin(GPIOB, GPIO_PIN_2, GPIO_PIN_RESET);
      HAL_GPIO_WritePin(GPIOB, GPIO_PIN_1, GPIO_PIN_RESET);
      HAL_Delay(100);
      //init motor
      HAL_GPIO_WritePin(GPIOB, GPIO_PIN_1, GPIO_PIN_SET);   //
      HAL_GPIO_WritePin(GPIOB, GPIO_PIN_2, GPIO_PIN_RESET); //
      //防抱�?????????????????????????????????????????????

      __HAL_TIM_SET_COMPARE(&htim3, TIM_CHANNEL_3, 0);
      HAL_TIM_PWM_Stop(&htim3, TIM_CHANNEL_3);

      //HAL_GPIO_WritePin(GPIOB, GPIO_PIN_1, GPIO_PIN_RESET);
      HAL_Delay(3000);
    }
  }

  ///////////////////*************************************************/////////////////////////////////////////
  ///////////////////**************************  7  *******************/////////////////////////////////////////
  ///////////////////*************************************************/////////////////////////////////////////

  // 7 底盘车摇�????????????????????? dipancheyaojin
  //PD7 A25底盘车遥进按钮手�?????????????????????????????????????????????                                重要6    [按钮  外部中断]
  //已捕获PD7 底盘车手动驶�?????????????????????????????????????????????
  if (GPIO_Pin == GPIO_PIN_7)
  {
    pdx[4] = !HAL_GPIO_ReadPin(GPIOD, GPIO_PIN_4);
    pdx[5] = !HAL_GPIO_ReadPin(GPIOD, GPIO_PIN_5);
    pdx[9] = !HAL_GPIO_ReadPin(GPIOD, GPIO_PIN_9);

    pdx[15] = !HAL_GPIO_ReadPin(GPIOD, GPIO_PIN_15);

    pbx[7] = HAL_GPIO_ReadPin(GPIOB, GPIO_PIN_7);
    pbx[6] = HAL_GPIO_ReadPin(GPIOB, GPIO_PIN_6);
    if (pdx[5] && pbx[7] && (!pbx[6]) && pdx[15] && (!pdx[9]))
    {
      HAL_TIM_PWM_Start(&htim3, TIM_CHANNEL_3); //PB0    A03  底盘车电�?????????????????????????????????????????????  �?????????????????????????????????????????????个触�?????????????????????????????????????????????
                                                // // HAL_TIM_PWM_Stop(&htim3, TIM_CHANNEL_3);
                                                // // HAL_TIM_PWM_Stop(&htim3, TIM_CHANNEL_4);
      // PB0   __HAL_TIM_SET_COMPARE(&htim3, TIM_CHANNEL_3, 0);

      __HAL_TIM_SET_COMPARE(&htim3, TIM_CHANNEL_3, 0);
      // HAL_GPIO_WritePin(GPIOB, GPIO_PIN_1, GPIO_PIN_RESET);
      // PB1   __HAL_TIM_SET_COMPARE(&htim3, TIM_CHANNEL_4, 0);
      HAL_Delay(1);
      //init motor
      HAL_GPIO_WritePin(GPIOB, GPIO_PIN_1, GPIO_PIN_SET);   //
      HAL_GPIO_WritePin(GPIOB, GPIO_PIN_2, GPIO_PIN_RESET); //

      __HAL_TIM_SET_COMPARE(&htim3, TIM_CHANNEL_3, 1000);
      HAL_Delay(1);
      HAL_GPIO_WritePin(GPIOB, GPIO_PIN_2, GPIO_PIN_RESET);
      HAL_GPIO_WritePin(GPIOB, GPIO_PIN_1, GPIO_PIN_RESET);

      HAL_GPIO_WritePin(GPIOB, GPIO_PIN_2, GPIO_PIN_RESET);
      HAL_Delay(5000);
      //init motor
      HAL_GPIO_WritePin(GPIOB, GPIO_PIN_1, GPIO_PIN_SET);   //
      HAL_GPIO_WritePin(GPIOB, GPIO_PIN_2, GPIO_PIN_RESET); //

      __HAL_TIM_SET_COMPARE(&htim3, TIM_CHANNEL_3, 500);
      HAL_GPIO_WritePin(GPIOB, GPIO_PIN_2, GPIO_PIN_SET);
      HAL_GPIO_WritePin(GPIOB, GPIO_PIN_1, GPIO_PIN_SET);
      HAL_Delay(100);
      //init motor
      HAL_GPIO_WritePin(GPIOB, GPIO_PIN_1, GPIO_PIN_SET);   //
      HAL_GPIO_WritePin(GPIOB, GPIO_PIN_2, GPIO_PIN_RESET); //
      //防抱�?????????????????????????????????????????????

      __HAL_TIM_SET_COMPARE(&htim3, TIM_CHANNEL_3, 0);
      HAL_TIM_PWM_Stop(&htim3, TIM_CHANNEL_3);

      //HAL_GPIO_WritePin(GPIOB, GPIO_PIN_1, GPIO_PIN_RESET);
      HAL_Delay(3000);
    }
    if (pdx[5] && pbx[7] && (!pbx[6]) && pdx[15] && pdx[9])
    {
      HAL_TIM_PWM_Start(&htim3, TIM_CHANNEL_3); //PB0    A03  底盘车电�?????????????????????????????????????????????  �?????????????????????????????????????????????个触�?????????????????????????????????????????????
                                                // // HAL_TIM_PWM_Stop(&htim3, TIM_CHANNEL_3);
                                                // // HAL_TIM_PWM_Stop(&htim3, TIM_CHANNEL_4);
      // PB0   __HAL_TIM_SET_COMPARE(&htim3, TIM_CHANNEL_3, 0);

      __HAL_TIM_SET_COMPARE(&htim3, TIM_CHANNEL_3, 0);
      // HAL_GPIO_WritePin(GPIOB, GPIO_PIN_1, GPIO_PIN_RESET);
      // PB1   __HAL_TIM_SET_COMPARE(&htim3, TIM_CHANNEL_4, 0);
      HAL_Delay(1);
      //init motor
      HAL_GPIO_WritePin(GPIOB, GPIO_PIN_1, GPIO_PIN_SET);   //
      HAL_GPIO_WritePin(GPIOB, GPIO_PIN_2, GPIO_PIN_RESET); //

      __HAL_TIM_SET_COMPARE(&htim3, TIM_CHANNEL_3, 1000);
      HAL_Delay(1);
      HAL_GPIO_WritePin(GPIOB, GPIO_PIN_2, GPIO_PIN_RESET);
      HAL_GPIO_WritePin(GPIOB, GPIO_PIN_1, GPIO_PIN_RESET);

      HAL_GPIO_WritePin(GPIOB, GPIO_PIN_2, GPIO_PIN_RESET);
      HAL_Delay(5000);
      //init motor
      HAL_GPIO_WritePin(GPIOB, GPIO_PIN_1, GPIO_PIN_SET);   //
      HAL_GPIO_WritePin(GPIOB, GPIO_PIN_2, GPIO_PIN_RESET); //

      __HAL_TIM_SET_COMPARE(&htim3, TIM_CHANNEL_3, 500);
      HAL_GPIO_WritePin(GPIOB, GPIO_PIN_2, GPIO_PIN_SET);
      HAL_GPIO_WritePin(GPIOB, GPIO_PIN_1, GPIO_PIN_SET);
      HAL_Delay(100);
      //init motor
      HAL_GPIO_WritePin(GPIOB, GPIO_PIN_1, GPIO_PIN_SET);   //
      HAL_GPIO_WritePin(GPIOB, GPIO_PIN_2, GPIO_PIN_RESET); //
      //防抱�?????????????????????????????????????????????

      __HAL_TIM_SET_COMPARE(&htim3, TIM_CHANNEL_3, 0);
      HAL_TIM_PWM_Stop(&htim3, TIM_CHANNEL_3);

      //HAL_GPIO_WritePin(GPIOB, GPIO_PIN_1, GPIO_PIN_RESET);
      HAL_Delay(3000);
    }
    HAL_GPIO_WritePin(GPIOD, GPIO_PIN_6, GPIO_PIN_SET);
  }
  ///////////////////*************************************************/////////////////////////////////////////
  ///////////////////**************************  10  *******************/////////////////////////////////////////
  ///////////////////*************************************************/////////////////////////////////////////

  //PD10 A30接地�?????????????????????????????????????????????合闸输入按钮                               重要8    [按钮  外部中断]
  //PB7继电器�?�开关必须使�?????????????????????????????????????????????
  //已捕获PD10 接地�?????????????????????????????????????????????手动合闸  接地�?????????????????????????????????????????????电机反转PB8 = 1 , PB9 = 0 �????????????????????????????????????????????? !远控允许PD9必为0  �????????????????????????????????????????????? 底盘车试验位置PD4 �????????????????????????????????????????????? PB7继电器�?�开关必须使能为1 �?????????????????????????????????????????????  !PB6 断路器必须分�????????????????????????????????????????????? �????????????????????????????????????????????? PD13 接地�?????????????????????????????????????????????机构分闸位置（信号快)  �????????????????????????????????????????????? PD15 接地�?????????????????????????????????????????????分闸位置
  // 10 接地�?????????????????????合闸 jiedidaohezha
  if (GPIO_Pin == GPIO_PIN_10)
  {
    pdx[4] = !HAL_GPIO_ReadPin(GPIOD, GPIO_PIN_4);
    pdx[9] = !HAL_GPIO_ReadPin(GPIOD, GPIO_PIN_9);

    pdx[15] = !HAL_GPIO_ReadPin(GPIOD, GPIO_PIN_15);

    pbx[7] = HAL_GPIO_ReadPin(GPIOB, GPIO_PIN_7);
    pbx[6] = HAL_GPIO_ReadPin(GPIOB, GPIO_PIN_6);
    if (pdx[4] && pbx[7] && (!pbx[6]) && pdx[15] && (!pdx[9]))
    {
      HAL_TIM_PWM_Start(&htim3, TIM_CHANNEL_3); //PB0    A03  底盘车电�?????????????????????????????????????????????  �?????????????????????????????????????????????个触�?????????????????????????????????????????????
                                                // // HAL_TIM_PWM_Stop(&htim3, TIM_CHANNEL_3);
                                                // // HAL_TIM_PWM_Stop(&htim3, TIM_CHANNEL_4);
      // PB0   __HAL_TIM_SET_COMPARE(&htim3, TIM_CHANNEL_3, 0);

      __HAL_TIM_SET_COMPARE(&htim3, TIM_CHANNEL_3, 0);
      // HAL_GPIO_WritePin(GPIOB, GPIO_PIN_1, GPIO_PIN_RESET);
      // PB1   __HAL_TIM_SET_COMPARE(&htim3, TIM_CHANNEL_4, 0);
      HAL_Delay(1);
      //init motor
      HAL_GPIO_WritePin(GPIOB, GPIO_PIN_10, GPIO_PIN_SET);   //
      HAL_GPIO_WritePin(GPIOB, GPIO_PIN_11, GPIO_PIN_RESET); //

      __HAL_TIM_SET_COMPARE(&htim3, TIM_CHANNEL_3, 1000);
      HAL_Delay(1);
      HAL_GPIO_WritePin(GPIOB, GPIO_PIN_10, GPIO_PIN_RESET);
      HAL_GPIO_WritePin(GPIOB, GPIO_PIN_11, GPIO_PIN_RESET);

      HAL_Delay(5000);
      //init motor
      HAL_GPIO_WritePin(GPIOB, GPIO_PIN_10, GPIO_PIN_SET);   //
      HAL_GPIO_WritePin(GPIOB, GPIO_PIN_11, GPIO_PIN_RESET); //

      __HAL_TIM_SET_COMPARE(&htim3, TIM_CHANNEL_3, 500);
      HAL_GPIO_WritePin(GPIOB, GPIO_PIN_10, GPIO_PIN_SET);
      HAL_GPIO_WritePin(GPIOB, GPIO_PIN_11, GPIO_PIN_SET);
      HAL_Delay(100);
      //init motor
      HAL_GPIO_WritePin(GPIOB, GPIO_PIN_10, GPIO_PIN_SET);   //
      HAL_GPIO_WritePin(GPIOB, GPIO_PIN_11, GPIO_PIN_RESET); //
      //防抱�?????????????????????????????????????????????

      __HAL_TIM_SET_COMPARE(&htim3, TIM_CHANNEL_3, 0);
      HAL_TIM_PWM_Stop(&htim3, TIM_CHANNEL_3);

      //HAL_GPIO_WritePin(GPIOB, GPIO_PIN_1, GPIO_PIN_RESET);
      HAL_Delay(3000);
    }
    if (((!pdx[4]) || (!pdx[5])) && pbx[7] && (!pbx[6]) && pdx[15] && (!pdx[9]))
    {
      HAL_TIM_PWM_Start(&htim3, TIM_CHANNEL_3); //PB0    A03  底盘车电�?????????????????????????????????????????????  �?????????????????????????????????????????????个触�?????????????????????????????????????????????
                                                // // HAL_TIM_PWM_Stop(&htim3, TIM_CHANNEL_3);
                                                // // HAL_TIM_PWM_Stop(&htim3, TIM_CHANNEL_4);
      // PB0   __HAL_TIM_SET_COMPARE(&htim3, TIM_CHANNEL_3, 0);

      __HAL_TIM_SET_COMPARE(&htim3, TIM_CHANNEL_3, 0);
      // HAL_GPIO_WritePin(GPIOB, GPIO_PIN_1, GPIO_PIN_RESET);
      // PB1   __HAL_TIM_SET_COMPARE(&htim3, TIM_CHANNEL_4, 0);
      HAL_Delay(1);
      //init motor
      HAL_GPIO_WritePin(GPIOB, GPIO_PIN_10, GPIO_PIN_SET);   //
      HAL_GPIO_WritePin(GPIOB, GPIO_PIN_11, GPIO_PIN_RESET); //

      __HAL_TIM_SET_COMPARE(&htim3, TIM_CHANNEL_3, 1000);
      HAL_Delay(1);
      HAL_GPIO_WritePin(GPIOB, GPIO_PIN_10, GPIO_PIN_RESET);
      HAL_GPIO_WritePin(GPIOB, GPIO_PIN_11, GPIO_PIN_RESET);

      HAL_Delay(5000);
      //init motor
      HAL_GPIO_WritePin(GPIOB, GPIO_PIN_10, GPIO_PIN_SET);   //
      HAL_GPIO_WritePin(GPIOB, GPIO_PIN_11, GPIO_PIN_RESET); //

      __HAL_TIM_SET_COMPARE(&htim3, TIM_CHANNEL_3, 500);
      HAL_GPIO_WritePin(GPIOB, GPIO_PIN_10, GPIO_PIN_SET);
      HAL_GPIO_WritePin(GPIOB, GPIO_PIN_11, GPIO_PIN_SET);
      HAL_Delay(100);
      //init motor
      HAL_GPIO_WritePin(GPIOB, GPIO_PIN_10, GPIO_PIN_SET);   //
      HAL_GPIO_WritePin(GPIOB, GPIO_PIN_11, GPIO_PIN_RESET); //
      //防抱�?????????????????????????????????????????????

      __HAL_TIM_SET_COMPARE(&htim3, TIM_CHANNEL_3, 0);
      HAL_TIM_PWM_Stop(&htim3, TIM_CHANNEL_3);

      //HAL_GPIO_WritePin(GPIOB, GPIO_PIN_1, GPIO_PIN_RESET);
      HAL_Delay(3000);
    }
    if (pdx[4] && pbx[7] && (!pbx[6]) && pdx[15] && pdx[9])
    {
      HAL_TIM_PWM_Start(&htim3, TIM_CHANNEL_3); //PB0    A03  底盘车电�?????????????????????????????????????????????  �?????????????????????????????????????????????个触�?????????????????????????????????????????????
                                                // // HAL_TIM_PWM_Stop(&htim3, TIM_CHANNEL_3);
                                                // // HAL_TIM_PWM_Stop(&htim3, TIM_CHANNEL_4);
      // PB0   __HAL_TIM_SET_COMPARE(&htim3, TIM_CHANNEL_3, 0);

      __HAL_TIM_SET_COMPARE(&htim3, TIM_CHANNEL_3, 0);
      // HAL_GPIO_WritePin(GPIOB, GPIO_PIN_1, GPIO_PIN_RESET);
      // PB1   __HAL_TIM_SET_COMPARE(&htim3, TIM_CHANNEL_4, 0);
      HAL_Delay(1);
      //init motor
      HAL_GPIO_WritePin(GPIOB, GPIO_PIN_10, GPIO_PIN_SET);   //
      HAL_GPIO_WritePin(GPIOB, GPIO_PIN_11, GPIO_PIN_RESET); //

      __HAL_TIM_SET_COMPARE(&htim3, TIM_CHANNEL_3, 1000);
      HAL_Delay(1);
      HAL_GPIO_WritePin(GPIOB, GPIO_PIN_10, GPIO_PIN_RESET);
      HAL_GPIO_WritePin(GPIOB, GPIO_PIN_11, GPIO_PIN_RESET);

      HAL_Delay(5000);
      //init motor
      HAL_GPIO_WritePin(GPIOB, GPIO_PIN_10, GPIO_PIN_SET);   //
      HAL_GPIO_WritePin(GPIOB, GPIO_PIN_11, GPIO_PIN_RESET); //

      __HAL_TIM_SET_COMPARE(&htim3, TIM_CHANNEL_3, 500);
      HAL_GPIO_WritePin(GPIOB, GPIO_PIN_10, GPIO_PIN_SET);
      HAL_GPIO_WritePin(GPIOB, GPIO_PIN_11, GPIO_PIN_SET);
      HAL_Delay(100);
      //init motor
      HAL_GPIO_WritePin(GPIOB, GPIO_PIN_10, GPIO_PIN_SET);   //
      HAL_GPIO_WritePin(GPIOB, GPIO_PIN_11, GPIO_PIN_RESET); //
      //防抱�?????????????????????????????????????????????

      __HAL_TIM_SET_COMPARE(&htim3, TIM_CHANNEL_3, 0);
      HAL_TIM_PWM_Stop(&htim3, TIM_CHANNEL_3);

      //HAL_GPIO_WritePin(GPIOB, GPIO_PIN_1, GPIO_PIN_RESET);
      HAL_Delay(3000);
    }
    if (((!pdx[4]) || (!pdx[5])) && pbx[7] && (!pbx[6]) && pdx[15] && pdx[9])
    {
      HAL_TIM_PWM_Start(&htim3, TIM_CHANNEL_3); //PB0    A03  底盘车电�?????????????????????????????????????????????  �?????????????????????????????????????????????个触�?????????????????????????????????????????????
                                                // // HAL_TIM_PWM_Stop(&htim3, TIM_CHANNEL_3);
                                                // // HAL_TIM_PWM_Stop(&htim3, TIM_CHANNEL_4);
      // PB0   __HAL_TIM_SET_COMPARE(&htim3, TIM_CHANNEL_3, 0);

      __HAL_TIM_SET_COMPARE(&htim3, TIM_CHANNEL_3, 0);
      // HAL_GPIO_WritePin(GPIOB, GPIO_PIN_1, GPIO_PIN_RESET);
      // PB1   __HAL_TIM_SET_COMPARE(&htim3, TIM_CHANNEL_4, 0);
      HAL_Delay(1);
      //init motor
      HAL_GPIO_WritePin(GPIOB, GPIO_PIN_10, GPIO_PIN_SET);   //
      HAL_GPIO_WritePin(GPIOB, GPIO_PIN_11, GPIO_PIN_RESET); //

      __HAL_TIM_SET_COMPARE(&htim3, TIM_CHANNEL_3, 1000);
      HAL_Delay(1);
      HAL_GPIO_WritePin(GPIOB, GPIO_PIN_10, GPIO_PIN_RESET);
      HAL_GPIO_WritePin(GPIOB, GPIO_PIN_11, GPIO_PIN_RESET);

      HAL_Delay(5000);
      //init motor
      HAL_GPIO_WritePin(GPIOB, GPIO_PIN_10, GPIO_PIN_SET);   //
      HAL_GPIO_WritePin(GPIOB, GPIO_PIN_11, GPIO_PIN_RESET); //

      __HAL_TIM_SET_COMPARE(&htim3, TIM_CHANNEL_3, 500);
      HAL_GPIO_WritePin(GPIOB, GPIO_PIN_10, GPIO_PIN_SET);
      HAL_GPIO_WritePin(GPIOB, GPIO_PIN_11, GPIO_PIN_SET);
      HAL_Delay(100);
      //init motor
      HAL_GPIO_WritePin(GPIOB, GPIO_PIN_10, GPIO_PIN_SET);   //
      HAL_GPIO_WritePin(GPIOB, GPIO_PIN_11, GPIO_PIN_RESET); //
      //防抱�?????????????????????????????????????????????

      __HAL_TIM_SET_COMPARE(&htim3, TIM_CHANNEL_3, 0);
      HAL_TIM_PWM_Stop(&htim3, TIM_CHANNEL_3);

      //HAL_GPIO_WritePin(GPIOB, GPIO_PIN_1, GPIO_PIN_RESET);
      HAL_Delay(3000);
    }
    HAL_GPIO_WritePin(GPIOD, GPIO_PIN_10, GPIO_PIN_SET);
  }
  ///////////////////*************************************************/////////////////////////////////////////
  ///////////////////**************************  11  *******************/////////////////////////////////////////
  ///////////////////*************************************************/////////////////////////////////////////

  //   PD11 A31接地�?????????????????????????????????????????????分闸输入按钮                               重要3    [按钮  外部中断]
  //    11 接地�?????????????????????分闸 jiedidaofenzha
  if (GPIO_Pin == GPIO_PIN_11)
  {
    //PB7继电器�?�开关必须使�?????????????????????????????????????????????
    //已捕获PD10 接地�?????????????????????????????????????????????手动合闸  接地�?????????????????????????????????????????????电机反转PB8 = 1 , PB9 = 0 �????????????????????????????????????????????? !远控允许PD9必为0  �????????????????????????????????????????????? 底盘车试验位置PD4 �????????????????????????????????????????????? PB7继电器�?�开关必须使能为1 �?????????????????????????????????????????????  !PB6 断路器必须分�????????????????????????????????????????????? �????????????????????????????????????????????? PD12 接地�?????????????????????????????????????????????机构合闸位置（信号快)  �????????????????????????????????????????????? PD14 接地�?????????????????????????????????????????????合闸位置
    pdx[4] = !HAL_GPIO_ReadPin(GPIOD, GPIO_PIN_4);
    pdx[9] = !HAL_GPIO_ReadPin(GPIOD, GPIO_PIN_9);

    pdx[14] = !HAL_GPIO_ReadPin(GPIOD, GPIO_PIN_14);

    pbx[7] = HAL_GPIO_ReadPin(GPIOB, GPIO_PIN_7);
    pbx[6] = HAL_GPIO_ReadPin(GPIOB, GPIO_PIN_6);

    if (pdx[4] && pbx[7] && (!pbx[6]) && pdx[14] && (!pdx[9]))
    {
      HAL_TIM_PWM_Start(&htim3, TIM_CHANNEL_3); //PB0    A03  底盘车电�?????????????????????????????????????????????  �?????????????????????????????????????????????个触�?????????????????????????????????????????????
                                                // // HAL_TIM_PWM_Stop(&htim3, TIM_CHANNEL_3);
                                                // // HAL_TIM_PWM_Stop(&htim3, TIM_CHANNEL_4);
      // PB0   __HAL_TIM_SET_COMPARE(&htim3, TIM_CHANNEL_3, 0);

      __HAL_TIM_SET_COMPARE(&htim3, TIM_CHANNEL_3, 0);
      // HAL_GPIO_WritePin(GPIOB, GPIO_PIN_1, GPIO_PIN_RESET);
      // PB1   __HAL_TIM_SET_COMPARE(&htim3, TIM_CHANNEL_4, 0);
      HAL_Delay(1);
      //init motor
      HAL_GPIO_WritePin(GPIOB, GPIO_PIN_10, GPIO_PIN_SET);   //
      HAL_GPIO_WritePin(GPIOB, GPIO_PIN_11, GPIO_PIN_RESET); //

      __HAL_TIM_SET_COMPARE(&htim3, TIM_CHANNEL_3, 1000);
      HAL_Delay(1);
      HAL_GPIO_WritePin(GPIOB, GPIO_PIN_10, GPIO_PIN_SET);
      HAL_GPIO_WritePin(GPIOB, GPIO_PIN_11, GPIO_PIN_SET);

      HAL_Delay(5000);
      //init motor
      HAL_GPIO_WritePin(GPIOB, GPIO_PIN_10, GPIO_PIN_SET);   //
      HAL_GPIO_WritePin(GPIOB, GPIO_PIN_11, GPIO_PIN_RESET); //

      __HAL_TIM_SET_COMPARE(&htim3, TIM_CHANNEL_3, 500);
      HAL_GPIO_WritePin(GPIOB, GPIO_PIN_10, GPIO_PIN_RESET);
      HAL_GPIO_WritePin(GPIOB, GPIO_PIN_11, GPIO_PIN_RESET);
      HAL_Delay(100);
      //init motor
      HAL_GPIO_WritePin(GPIOB, GPIO_PIN_10, GPIO_PIN_SET);   //
      HAL_GPIO_WritePin(GPIOB, GPIO_PIN_11, GPIO_PIN_RESET); //
      //防抱�?????????????????????????????????????????????

      __HAL_TIM_SET_COMPARE(&htim3, TIM_CHANNEL_3, 0);
      HAL_TIM_PWM_Stop(&htim3, TIM_CHANNEL_3);

      //HAL_GPIO_WritePin(GPIOB, GPIO_PIN_1, GPIO_PIN_RESET);
      HAL_Delay(3000);
    }
    if (pdx[4] && pbx[7] && (!pbx[6]) && pdx[14] && pdx[9])
    {
      HAL_TIM_PWM_Start(&htim3, TIM_CHANNEL_3); //PB0    A03  底盘车电�?????????????????????????????????????????????  �?????????????????????????????????????????????个触�?????????????????????????????????????????????
                                                // // HAL_TIM_PWM_Stop(&htim3, TIM_CHANNEL_3);
                                                // // HAL_TIM_PWM_Stop(&htim3, TIM_CHANNEL_4);
      // PB0   __HAL_TIM_SET_COMPARE(&htim3, TIM_CHANNEL_3, 0);

      __HAL_TIM_SET_COMPARE(&htim3, TIM_CHANNEL_3, 0);
      // HAL_GPIO_WritePin(GPIOB, GPIO_PIN_1, GPIO_PIN_RESET);
      // PB1   __HAL_TIM_SET_COMPARE(&htim3, TIM_CHANNEL_4, 0);
      HAL_Delay(1);
      //init motor
      HAL_GPIO_WritePin(GPIOB, GPIO_PIN_10, GPIO_PIN_SET);   //
      HAL_GPIO_WritePin(GPIOB, GPIO_PIN_11, GPIO_PIN_RESET); //

      __HAL_TIM_SET_COMPARE(&htim3, TIM_CHANNEL_3, 1000);
      HAL_Delay(1);
      HAL_GPIO_WritePin(GPIOB, GPIO_PIN_10, GPIO_PIN_SET);
      HAL_GPIO_WritePin(GPIOB, GPIO_PIN_11, GPIO_PIN_SET);

      HAL_Delay(5000);
      //init motor
      HAL_GPIO_WritePin(GPIOB, GPIO_PIN_10, GPIO_PIN_SET);   //
      HAL_GPIO_WritePin(GPIOB, GPIO_PIN_11, GPIO_PIN_RESET); //

      __HAL_TIM_SET_COMPARE(&htim3, TIM_CHANNEL_3, 500);
      HAL_GPIO_WritePin(GPIOB, GPIO_PIN_10, GPIO_PIN_RESET);
      HAL_GPIO_WritePin(GPIOB, GPIO_PIN_11, GPIO_PIN_RESET);
      HAL_Delay(100);
      //init motor
      HAL_GPIO_WritePin(GPIOB, GPIO_PIN_10, GPIO_PIN_SET);   //
      HAL_GPIO_WritePin(GPIOB, GPIO_PIN_11, GPIO_PIN_RESET); //
      //防抱�?????????????????????????????????????????????

      __HAL_TIM_SET_COMPARE(&htim3, TIM_CHANNEL_3, 0);
      HAL_TIM_PWM_Stop(&htim3, TIM_CHANNEL_3);

      //HAL_GPIO_WritePin(GPIOB, GPIO_PIN_1, GPIO_PIN_RESET);
      HAL_Delay(3000);
    }
    HAL_GPIO_WritePin(GPIOD, GPIO_PIN_11, GPIO_PIN_SET);
  }
  HAL_Delay(100);
  __HAL_GPIO_EXTI_CLEAR_IT(GPIO_Pin);
}

/* USER CODE END 4 */

void Error_Handler(void)
{
  __disable_irq();
  while (1)
  {
  }
}

/************************ (C) COPYRIGHT STMicroelectronics *****END OF FILE****/
